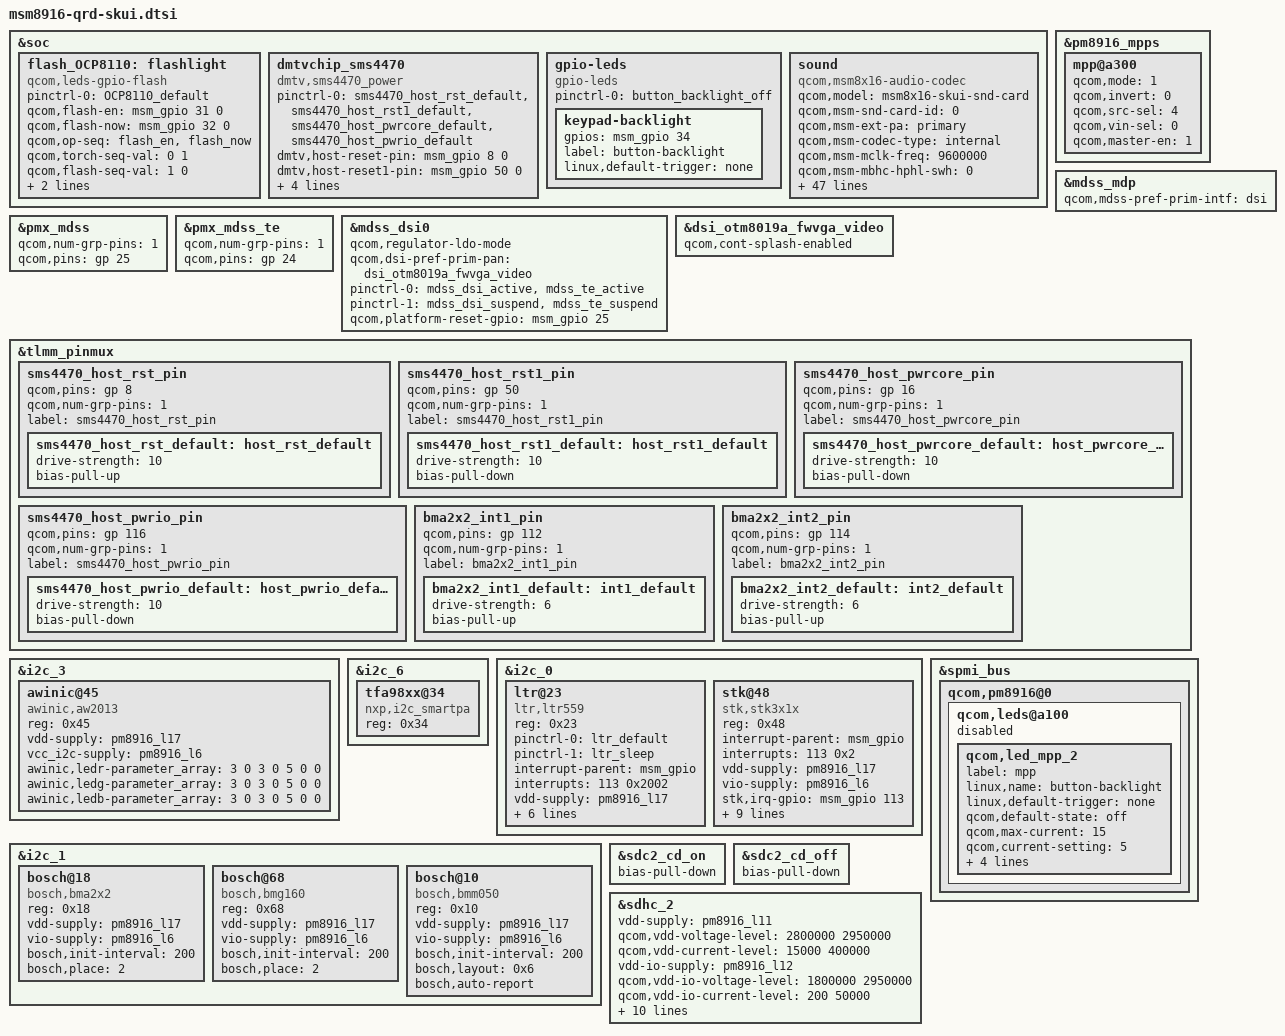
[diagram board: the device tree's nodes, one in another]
/* Copyright (c) 2014, The Linux Foundation. All rights reserved.
 *
 * This program is free software; you can redistribute it and/or modify
 * it under the terms of the GNU General Public License version 2 and
 * only version 2 as published by the Free Software Foundation.
 *
 * This program is distributed in the hope that it will be useful,
 * but WITHOUT ANY WARRANTY; without even the implied warranty of
 * MERCHANTABILITY or FITNESS FOR A PARTICULAR PURPOSE.  See the
 * GNU General Public License for more details.
 */

#include "msm8916-qrd.dtsi"
#include "dsi-panel-otm8019a-fwvga-video.dtsi"
#include "msm8916-camera-sensor-qrd-skui.dtsi"
#include "dsi-panel-trulyk70334-720p-video.dtsi"
#include "dsi-panel-trulyHX8394D-720p-video.dtsi"
#include "dsi-panel-boyiotm1284a-720p-video.dtsi"
#include "dsi-panel-trulyotm1288a-720p-cmd.dtsi"
#include "dsi-panel-new-trulyotm1288a-720p-cmd.dtsi"
#include "dsi-panel-trulyotm1288a-720p-video.dtsi"

&soc {
	flash_OCP8110:flashlight {
		compatible = "qcom,leds-gpio-flash";
		status = "okay";
		pinctrl-names = "flash_default";
		pinctrl-0 = <&OCP8110_default>;
		qcom,flash-en = <&msm_gpio 31 0>;
		qcom,flash-now = <&msm_gpio 32 0>;
		qcom,op-seq = "flash_en", "flash_now";
		qcom,torch-seq-val = <0 1>;
		qcom,flash-seq-val = <1 0>;
		linux,name = "flashlight";
		linux,default-trigger = "flashlight-trigger";
	};

	dmtvchip_sms4470{
		compatible = "dmtv,sms4470_power";
		status = "okay";
		pinctrl-names = "default";
		pinctrl-0 = <&sms4470_host_rst_default &sms4470_host_rst1_default &sms4470_host_pwrcore_default &sms4470_host_pwrio_default>;
		dmtv,host-reset-pin = <&msm_gpio 8 0>;
		dmtv,host-reset1-pin = <&msm_gpio 50 0>;
		dmtv,host-powercore-pin = <&msm_gpio 16 0>;
		dmtv,host-powerio-pin = <&msm_gpio 116 0>;
		vdd-io-supply = <&pm8916_l12>;
		vdd-emi-supply = <&pm8916_l16>;
	};

	gpio-leds {
		compatible = "gpio-leds";
		status = "okay";
		pinctrl-names = "default";
		pinctrl-0 = <&button_backlight_off>;

		keypad-backlight {
			gpios = <&msm_gpio 34 0>;
			label = "button-backlight";
			linux,default-trigger = "none";
		};
	};

	sound {
		compatible = "qcom,msm8x16-audio-codec";
		qcom,model = "msm8x16-skui-snd-card";
		qcom,msm-snd-card-id = <0>;
		qcom,msm-ext-pa = "primary";
		qcom,msm-codec-type = "internal";
		qcom,msm-mclk-freq = <9600000>;
		qcom,msm-mbhc-hphl-swh = <0>;
		qcom,msm-mbhc-gnd-swh = <1>;
		qcom,msm-hs-micbias-type = "internal";
		qcom,audio-routing =
			"RX_BIAS", "MCLK",
			"SPK_RX_BIAS", "MCLK",
			"INT_LDO_H", "MCLK",
			"MIC BIAS Internal1", "Handset Mic", //changed here
			"MIC BIAS Internal2", "Headset Mic",
			"MIC BIAS Internal1", "Secondary Mic", //changed here
			"AMIC1", "MIC BIAS Internal1", //changed here
			"AMIC2", "MIC BIAS Internal2",
			"AMIC3", "MIC BIAS Internal1"; //changed here
		pinctrl-names = "cdc_lines_act",
				"cdc_lines_sus";
		pinctrl-0 = <&cdc_pdm_lines_act>;
		pinctrl-1 = <&cdc_pdm_lines_sus>;
		qcom,cdc_ext_earphone_pa = <&msm_gpio 51 0x0>;
		qcom,cdc_ext_earphone_pa_pwr = <&msm_gpio 52 0x0>;
		asoc-platform = <&pcm0>, <&pcm1>, <&voip>, <&voice>,
				<&loopback>, <&compress>, <&hostless>,
				<&afe>, <&lsm>, <&routing>, <&lpa>;
		asoc-platform-names = "msm-pcm-dsp.0", "msm-pcm-dsp.1",
				"msm-voip-dsp", "msm-pcm-voice", "msm-pcm-loopback",
				"msm-compress-dsp", "msm-pcm-hostless", "msm-pcm-afe",
				"msm-lsm-client", "msm-pcm-routing", "msm-pcm-lpa";
		asoc-cpu = <&dai_pri_auxpcm>, <&dai_hdmi>,
				<&dai_mi2s0>, <&dai_mi2s1>, <&dai_mi2s2>, <&dai_mi2s3>,
				<&sb_0_rx>, <&sb_0_tx>, <&sb_1_rx>, <&sb_1_tx>,
				<&sb_3_rx>, <&sb_3_tx>, <&sb_4_rx>, <&sb_4_tx>,
				<&bt_sco_rx>, <&bt_sco_tx>, <&int_fm_rx>, <&int_fm_tx>,
				<&afe_pcm_rx>, <&afe_pcm_tx>, <&afe_proxy_rx>, <&afe_proxy_tx>,
				<&incall_record_rx>, <&incall_record_tx>, <&incall_music_rx>,
				<&incall_music_2_rx>;
		asoc-cpu-names = "msm-dai-q6-auxpcm.1", "msm-dai-q6-hdmi.8",
				"msm-dai-q6-mi2s.0", "msm-dai-q6-mi2s.1",
				"msm-dai-q6-mi2s.2", "msm-dai-q6-mi2s.3",
				"msm-dai-q6-dev.16384", "msm-dai-q6-dev.16385",
				"msm-dai-q6-dev.16386", "msm-dai-q6-dev.16387",
				"msm-dai-q6-dev.16390", "msm-dai-q6-dev.16391",
				"msm-dai-q6-dev.16392", "msm-dai-q6-dev.16393",
				"msm-dai-q6-dev.12288", "msm-dai-q6-dev.12289",
				"msm-dai-q6-dev.12292", "msm-dai-q6-dev.12293",
				"msm-dai-q6-dev.224", "msm-dai-q6-dev.225",
				"msm-dai-q6-dev.241", "msm-dai-q6-dev.240",
				"msm-dai-q6-dev.32771", "msm-dai-q6-dev.32772",
				"msm-dai-q6-dev.32773", "msm-dai-q6-dev.32770";
		asoc-codec = <&stub_codec>, <&pm8916_tombak_dig>;
		asoc-codec-names = "msm-stub-codec.1", "tombak_codec";
	};
};

&pm8916_mpps {
	mpp@a300 { /* MPP 4 */
		/* Backlight PWM */
		qcom,mode = <1>;		/* Digital output */
		qcom,invert = <0>;		/* Disable invert */
		qcom,src-sel = <4>;		/* DTEST1 */
		qcom,vin-sel = <0>;		/* VPH_PWR */
		qcom,master-en = <1>;		/* Enable MPP */
	};
};

&mdss_mdp {
	qcom,mdss-pref-prim-intf = "dsi";
};

&pmx_mdss {
	qcom,num-grp-pins = <1>;
	qcom,pins = <&gp 25>;
};

&pmx_mdss_te {
	qcom,num-grp-pins = <1>;
	qcom,pins = <&gp 24>;
};

&mdss_dsi0 {
	qcom,regulator-ldo-mode;
	qcom,dsi-pref-prim-pan = <&dsi_otm8019a_fwvga_video>;
	pinctrl-names = "mdss_default", "mdss_sleep";
	pinctrl-0 = <&mdss_dsi_active &mdss_te_active>;
	pinctrl-1 = <&mdss_dsi_suspend &mdss_te_suspend>;

	qcom,platform-reset-gpio = <&msm_gpio 25 0>;
};

&dsi_otm8019a_fwvga_video {
       qcom,cont-splash-enabled;
};

&tlmm_pinmux {
	sms4470_host_rst_pin {
		qcom,pins = <&gp 8>;
		qcom,num-grp-pins = <1>;
		label = "sms4470_host_rst_pin";
		sms4470_host_rst_default: host_rst_default {
			  drive-strength = <10>;
			  bias-pull-up;
		};
	};

	sms4470_host_rst1_pin {
		qcom,pins = <&gp 50>;
		qcom,num-grp-pins = <1>;
		label = "sms4470_host_rst1_pin";
		sms4470_host_rst1_default: host_rst1_default {
			  drive-strength = <10>;
			  bias-pull-down;
		};
	};

	sms4470_host_pwrcore_pin {
		qcom,pins = <&gp 16>;
		qcom,num-grp-pins = <1>;
		label = "sms4470_host_pwrcore_pin";
		sms4470_host_pwrcore_default: host_pwrcore_default {
			  drive-strength = <10>;
			  bias-pull-down;
		};
	};

	sms4470_host_pwrio_pin {
		qcom,pins = <&gp 116>;
		qcom,num-grp-pins = <1>;
		label = "sms4470_host_pwrio_pin";
		sms4470_host_pwrio_default: host_pwrio_default {
			  drive-strength = <10>;
			  bias-pull-down;
		};
	};

	bma2x2_int1_pin {
		qcom,pins = <&gp 112>;
		qcom,num-grp-pins = <1>;
		label = "bma2x2_int1_pin";
		bma2x2_int1_default: int1_default {
			  drive-strength = <6>;
			  bias-pull-up;
		};
	};

	bma2x2_int2_pin {
		qcom,pins = <&gp 114>;
		qcom,num-grp-pins = <1>;
		label = "bma2x2_int2_pin";
		bma2x2_int2_default: int2_default {
			  drive-strength = <6>;
			  bias-pull-up;
		};
	};
};

&i2c_3{ /* BLSP1 QUP3 */
		awinic@45 { /* Breath Light-Driven */
			compatible = "awinic,aw2013";
			reg = <0x45>;
			vdd-supply = <&pm8916_l17>;
			vcc_i2c-supply = <&pm8916_l6>;
			awinic,ledr-parameter_array = <3 0 3 0 5 0 0>;
			awinic,ledg-parameter_array = <3 0 3 0 5 0 0>;
			awinic,ledb-parameter_array = <3 0 3 0 5 0 0>;
		};
};

&i2c_6{ /* BLSP1 QUP6 */
		tfa98xx@34 { /* nxp ext codec tfa98xx */

			compatible = "nxp,i2c_smartpa";
			reg = <0x34>;
		};
};

&i2c_0{ /* BLSP1 QUP2 */
	        ltr@23 { /* Ambient light and proximity sensor */
	                compatible = "ltr,ltr559";
	                reg = <0x23>;
			pinctrl-names = "default","sleep";
			pinctrl-0 = <&ltr_default>;
			pinctrl-1 = <&ltr_sleep>;
	                interrupt-parent = <&msm_gpio>;
	                interrupts = <113 0x2002>;
	                vdd-supply = <&pm8916_l17>;
	                vio-supply = <&pm8916_l6>;
	                liteon,intr = <113>;
	                ltr,irq-gpio = <&msm_gpio 113 0x2002>;
	                ltr,ps-threshold = <120>;
	                ltr,ps-hysteresis-threshold = <80>;
	                ltr,als-polling-time = <200>;
	        };

			stk@48 {
				compatible = "stk,stk3x1x";
				reg = <0x48>;
				interrupt-parent = <&msm_gpio>;
				interrupts = <113 0x2>;
				vdd-supply = <&pm8916_l17>;
				vio-supply = <&pm8916_l6>;
				stk,irq-gpio = <&msm_gpio 113 0x02>;
				stk,transmittance = <340>;
				stk,state-reg = <0x00>;
				stk,psctrl-reg = <0x71>;
				stk,alsctrl-reg = <0x38>;
				stk,ledctrl-reg = <0xFF>;
				stk,wait-reg = <0x07>;
				stk,ps-thdh = <150>;
				stk,ps-thdl = <100>;
				stk,use-fir;
			};
};

&i2c_1{ /* BLSP1 QUP1 */
		bosch@18 { /* Accelerometer sensor */
			compatible = "bosch,bma2x2";
			reg = <0x18>;
			vdd-supply = <&pm8916_l17>;
			vio-supply = <&pm8916_l6>;
			bosch,init-interval = <200>;
			bosch,place = <2>;
		};

		bosch@68 { /* Gyroscope sensor */
			compatible = "bosch,bmg160";
			reg = <0x68>;
			vdd-supply = <&pm8916_l17>;
			vio-supply = <&pm8916_l6>;
			bosch,init-interval = <200>;
			bosch,place = <2>;
		};

		bosch@10 {/* Magnetic sensor */
			compatible = "bosch,bmm050";
			reg = <0x10>;
			vdd-supply = <&pm8916_l17>;
			vio-supply = <&pm8916_l6>;
			bosch,init-interval = <200>;
			bosch,layout = <0x6>;
			bosch,auto-report;
		};
};

&spmi_bus {
        qcom,pm8916@0 {
                qcom,leds@a100 {
                        status = "disabled";
                        qcom,led_mpp_2 {
                                label = "mpp";
                                linux,name = "button-backlight";
                                linux,default-trigger = "none";
                                qcom,default-state = "off";
                                qcom,max-current = <15>;
                                qcom,current-setting = <5>;
                                qcom,id = <6>;
                                qcom,mode = "manual";
                                qcom,source-sel = <1>;
                                qcom,mode-ctrl = <0x60>;
                        };
                };
        };
};

&sdc2_cd_on {
	/delete-property/ bias-pull-up;
	bias-pull-down;
};

&sdc2_cd_off {
	/delete-property/ bias-disable;
	bias-pull-down;
};

&sdhc_2 {
	vdd-supply = <&pm8916_l11>;
	qcom,vdd-voltage-level = <2800000 2950000>;
	qcom,vdd-current-level = <15000 400000>;

	vdd-io-supply = <&pm8916_l12>;
	qcom,vdd-io-voltage-level = <1800000 2950000>;
	qcom,vdd-io-current-level = <200 50000>;

	pinctrl-names = "active", "sleep";
	pinctrl-0 = <&sdc2_clk_on &sdc2_cmd_on &sdc2_data_on &sdc2_cd_on>;
	pinctrl-1 = <&sdc2_clk_off &sdc2_cmd_off &sdc2_data_off &sdc2_cd_off>;

	#address-cells = <0>;
	interrupt-parent = <&sdhc_2>;
	interrupts = <0 1 2>;
	#interrupt-cells = <1>;
	interrupt-map-mask = <0xffffffff>;
	interrupt-map = <0 &intc 0 125 0
			1 &intc 0 221 0
			2 &msm_gpio 38 0>;
	interrupt-names = "hc_irq", "pwr_irq", "status_irq";
	cd-gpios = <&msm_gpio 38 0x1>;

	status = "ok";
};

